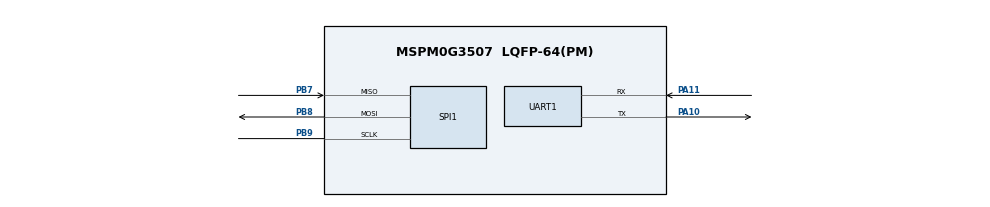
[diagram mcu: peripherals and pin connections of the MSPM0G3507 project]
//@cliArgs --device "MSPM0G350X" --package "LQFP-64(PM)" --part "Default"
//@v2CliArgs --device "MSPM0G3507" --package "LQFP-64(PM)"
// @cliArgs --board /ti/boards/LP_MSPM0G3507 --rtos nortos
// SysConfig for the Arduino compatibility layer on the LP-MSPM0G3507.
// Only the peripherals that need clock or pin-mux setup live here: SPI1 (display), UART0 (Serial,
// XDS110 backchannel), and the 32 MHz clock tree. Every plain GPIO pin is set up at run time
// by pinMode(), and Wire is bit-banged on GPIO, so no GPIO or I2C module is configured.
const SPI    = scripting.addModule("/ti/driverlib/SPI", {}, false);
const SPI1   = SPI.addInstance();
const UART   = scripting.addModule("/ti/driverlib/UART", {}, false);
const UART1  = UART.addInstance();
const Board  = scripting.addModule("/ti/driverlib/Board", {}, false);
const SYSCTL = scripting.addModule("/ti/driverlib/SYSCTL", {}, false);

SPI1.$name                      = "ARD_SPI";
SPI1.targetBitRate              = 8000000;
SPI1.frameFormat                = "MOTO3";
SPI1.peripheral.$assign         = "SPI1";
SPI1.peripheral.sclkPin.$assign = "PB9";
SPI1.peripheral.mosiPin.$assign = "PB8";
SPI1.peripheral.misoPin.$assign = "PB7";

UART1.$name                     = "ARD_UART";
UART1.targetBaudRate            = 115200;
UART1.peripheral.$assign        = "UART0";
UART1.peripheral.rxPin.$assign  = "PA11";
UART1.peripheral.txPin.$assign  = "PA10";

SYSCTL.forceDefaultClkConfig = true;
SYSCTL.clockTreeEn           = true;
